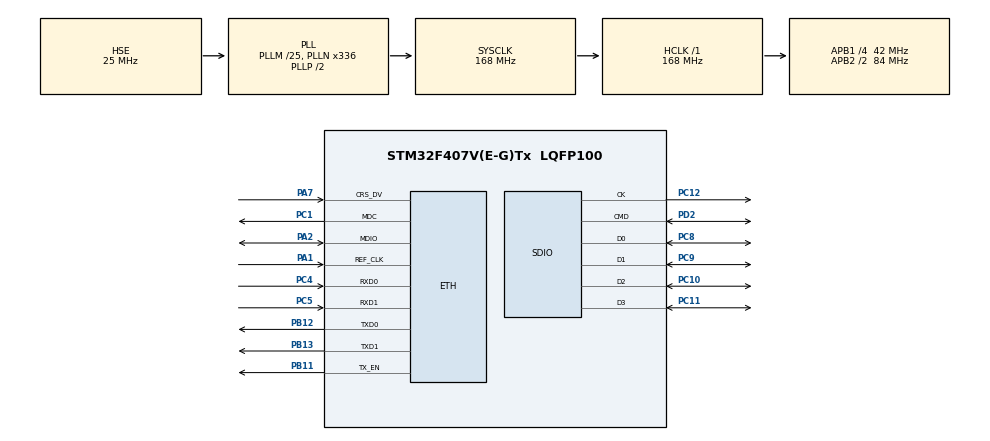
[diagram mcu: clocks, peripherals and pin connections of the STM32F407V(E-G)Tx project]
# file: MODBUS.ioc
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ETH.MediaInterface=HAL_ETH_RMII_MODE
FREERTOS.Tasks01=defaultTask,24,128,StartDefaultTask,Default,NULL,Dynamic,NULL,NULL
FREERTOS.configUSE_NEWLIB_REENTRANT=1
LWIP.BSP.number=1
LWIP.Version=v2.1.2_Cube
LWIP0.BSP.STBoard=false
LWIP0.BSP.api=BSP_COMPONENT_DRIVER
LWIP0.BSP.component=DP83848
LWIP0.BSP.instance=DP83848
LWIP0.BSP.name=Driver_PHY
LWIP0.BSP.semaphore=S_DP83848
LWIP0.BSP.solution=DP83848
Mcu.Family=STM32F4
Mcu.Name=STM32F407V(E-G)Tx
Mcu.Package=LQFP100
NVIC.ETH_IRQn=true\:5\:0\:false\:false\:true\:true\:false\:true\:true
NVIC.PriorityGroup=NVIC_PRIORITYGROUP_4
NVIC.TIM6_DAC_IRQn=true\:15\:0\:false\:false\:true\:false\:false\:true\:true
NVIC.TIM7_IRQn=true\:5\:0\:false\:false\:true\:true\:true\:true\:true
NVIC.TimeBase=TIM6_DAC_IRQn
NVIC.TimeBaseIP=TIM6
PA1.Mode=RMII
PA1.Signal=ETH_REF_CLK
PA13.Mode=Serial_Wire
PA13.Signal=SYS_JTMS-SWDIO
PA14.Mode=Serial_Wire
PA14.Signal=SYS_JTCK-SWCLK
PA2.Mode=RMII
PA2.Signal=ETH_MDIO
PA7.Mode=RMII
PA7.Signal=ETH_CRS_DV
PB11.Mode=RMII
PB11.Signal=ETH_TX_EN
PB12.Mode=RMII
PB12.Signal=ETH_TXD0
PB13.Mode=RMII
PB13.Signal=ETH_TXD1
PC1.Mode=RMII
PC1.Signal=ETH_MDC
PC10.Mode=SD_4_bits_Wide_bus
PC10.Signal=SDIO_D2
PC11.Mode=SD_4_bits_Wide_bus
PC11.Signal=SDIO_D3
PC12.Mode=SD_4_bits_Wide_bus
PC12.Signal=SDIO_CK
PC4.Mode=RMII
PC4.Signal=ETH_RXD0
PC5.Mode=RMII
PC5.Signal=ETH_RXD1
PC8.Mode=SD_4_bits_Wide_bus
PC8.Signal=SDIO_D0
PC9.Mode=SD_4_bits_Wide_bus
PC9.Signal=SDIO_D1
PD2.Mode=SD_4_bits_Wide_bus
PD2.Signal=SDIO_CMD
PH0-OSC_IN.Mode=HSE-External-Oscillator
PH0-OSC_IN.Signal=RCC_OSC_IN
PH1-OSC_OUT.Mode=HSE-External-Oscillator
PH1-OSC_OUT.Signal=RCC_OSC_OUT
ProjectManager.HeapSize=0x200
ProjectManager.StackSize=0x400
ProjectManager.TargetToolchain=STM32CubeIDE
RCC.48MHZClocksFreq_Value=48000000
RCC.AHBFreq_Value=168000000
RCC.APB1CLKDivider=RCC_HCLK_DIV4
RCC.APB1Freq_Value=42000000
RCC.APB1TimFreq_Value=84000000
RCC.APB2CLKDivider=RCC_HCLK_DIV2
RCC.APB2Freq_Value=84000000
RCC.APB2TimFreq_Value=168000000
RCC.CortexFreq_Value=168000000
RCC.EnbaleCSS=true
RCC.HCLKFreq_Value=168000000
RCC.HSE_VALUE=25000000
RCC.HSI_VALUE=16000000
RCC.LSE_VALUE=32768
RCC.PLLM=25
RCC.PLLN=336
RCC.PLLQ=7
RCC.PLLSourceVirtual=RCC_PLLSOURCE_HSE
RCC.SYSCLKFreq_VALUE=168000000
RCC.SYSCLKSource=RCC_SYSCLKSOURCE_PLLCLK
RCC.VCOOutputFreq_Value=336000000
TIM7.Period=249
TIM7.Prescaler=83
VP_FATFS_VS_SDIO.Mode=SDIO
VP_FREERTOS_VS_CMSIS_V2.Mode=CMSIS_V2
VP_LWIP_VS_Enabled.Mode=Enabled
VP_SYS_VS_tim6.Mode=TIM6
VP_TIM7_VS_ClockSourceINT.Mode=Enable_Timer
board=custom

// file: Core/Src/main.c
/* USER CODE BEGIN Header */
/**
  ******************************************************************************
  * @file           : main.c
  * @brief          : Main program body
  ******************************************************************************
  * @attention
  *
  * Copyright (c) 2026 STMicroelectronics.
  * All rights reserved.
  *
  * This software is licensed under terms that can be found in the LICENSE file
  * in the root directory of this software component.
  * If no LICENSE file comes with this software, it is provided AS-IS.
  *
  ******************************************************************************
  */
/* USER CODE END Header */
#include "main.h"
#include "cmsis_os.h"
#include "fatfs.h"
#include "lwip.h"

/* USER CODE BEGIN Includes */
#include "app_system.h"
#include "app_p10.h"
/* USER CODE END Includes */

SD_HandleTypeDef hsd;

TIM_HandleTypeDef htim7;

/* Definitions for defaultTask */
osThreadId_t defaultTaskHandle;
const osThreadAttr_t defaultTask_attributes = {
  .name = "defaultTask",
  .stack_size = 128 * 4,
  .priority = (osPriority_t) osPriorityNormal,
};

void SystemClock_Config(void);
static void MX_GPIO_Init(void);
static void MX_SDIO_SD_Init(void);
static void MX_TIM7_Init(void);
void StartDefaultTask(void *argument);

int main(void)
{

  /* MCU Configuration--------------------------------------------------------*/
  HAL_Init();

  SystemClock_Config();

  /* Initialize all configured peripherals */
  MX_GPIO_Init();
  MX_SDIO_SD_Init();
  MX_FATFS_Init();
  MX_TIM7_Init();

  /* USER CODE BEGIN 2 */
  APP_SystemEarlyInit();

  /* P10 GPIO init + start scan timer (TIM7) */
  APP_P10_Init();
  if (HAL_TIM_Base_Start_IT(&htim7) != HAL_OK)
  {
    Error_Handler();
  }
  /* USER CODE END 2 */

  /* Init scheduler */
  osKernelInitialize();

  /* Create the thread(s) */
  defaultTaskHandle = osThreadNew(StartDefaultTask, NULL, &defaultTask_attributes);

  /* Start scheduler */
  osKernelStart();

  /* Infinite loop */
  while (1)
  {
  }
}

void SystemClock_Config(void)
{
  RCC_OscInitTypeDef RCC_OscInitStruct = {0};
  RCC_ClkInitTypeDef RCC_ClkInitStruct = {0};

  __HAL_RCC_PWR_CLK_ENABLE();
  __HAL_PWR_VOLTAGESCALING_CONFIG(PWR_REGULATOR_VOLTAGE_SCALE1);

  RCC_OscInitStruct.OscillatorType = RCC_OSCILLATORTYPE_HSE;
  RCC_OscInitStruct.HSEState = RCC_HSE_ON;
  RCC_OscInitStruct.PLL.PLLState = RCC_PLL_ON;
  RCC_OscInitStruct.PLL.PLLSource = RCC_PLLSOURCE_HSE;
  RCC_OscInitStruct.PLL.PLLM = 25;
  RCC_OscInitStruct.PLL.PLLN = 336;
  RCC_OscInitStruct.PLL.PLLP = RCC_PLLP_DIV2;
  RCC_OscInitStruct.PLL.PLLQ = 7;
  if (HAL_RCC_OscConfig(&RCC_OscInitStruct) != HAL_OK)
  {
    Error_Handler();
  }

  RCC_ClkInitStruct.ClockType = RCC_CLOCKTYPE_HCLK|RCC_CLOCKTYPE_SYSCLK
                              |RCC_CLOCKTYPE_PCLK1|RCC_CLOCKTYPE_PCLK2;
  RCC_ClkInitStruct.SYSCLKSource = RCC_SYSCLKSOURCE_PLLCLK;
  RCC_ClkInitStruct.AHBCLKDivider = RCC_SYSCLK_DIV1;
  RCC_ClkInitStruct.APB1CLKDivider = RCC_HCLK_DIV4;
  RCC_ClkInitStruct.APB2CLKDivider = RCC_HCLK_DIV2;

  if (HAL_RCC_ClockConfig(&RCC_ClkInitStruct, FLASH_LATENCY_5) != HAL_OK)
  {
    Error_Handler();
  }

  HAL_RCC_EnableCSS();
}

static void MX_SDIO_SD_Init(void)
{
  hsd.Instance = SDIO;
  hsd.Init.ClockEdge = SDIO_CLOCK_EDGE_RISING;
  hsd.Init.ClockBypass = SDIO_CLOCK_BYPASS_DISABLE;
  hsd.Init.ClockPowerSave = SDIO_CLOCK_POWER_SAVE_DISABLE;
  hsd.Init.BusWide = SDIO_BUS_WIDE_4B;
  hsd.Init.HardwareFlowControl = SDIO_HARDWARE_FLOW_CONTROL_DISABLE;
  hsd.Init.ClockDiv = 0;
}

static void MX_TIM7_Init(void)
{
  TIM_MasterConfigTypeDef sMasterConfig = {0};

  htim7.Instance = TIM7;
  htim7.Init.Prescaler = 83;
  htim7.Init.CounterMode = TIM_COUNTERMODE_UP;
  htim7.Init.Period = 249;
  htim7.Init.AutoReloadPreload = TIM_AUTORELOAD_PRELOAD_DISABLE;
  if (HAL_TIM_Base_Init(&htim7) != HAL_OK)
  {
    Error_Handler();
  }
  sMasterConfig.MasterOutputTrigger = TIM_TRGO_RESET;
  sMasterConfig.MasterSlaveMode = TIM_MASTERSLAVEMODE_DISABLE;
  if (HAL_TIMEx_MasterConfigSynchronization(&htim7, &sMasterConfig) != HAL_OK)
  {
    Error_Handler();
  }
}

static void MX_GPIO_Init(void)
{
  __HAL_RCC_GPIOH_CLK_ENABLE();
  __HAL_RCC_GPIOC_CLK_ENABLE();
  __HAL_RCC_GPIOA_CLK_ENABLE();
  __HAL_RCC_GPIOB_CLK_ENABLE();
  __HAL_RCC_GPIOD_CLK_ENABLE();
}

void StartDefaultTask(void *argument)
{
  MX_LWIP_Init();

  /* USER CODE BEGIN 5 */
  APP_SystemStart();

  for(;;)
  {
    osDelay(1);
  }
  /* USER CODE END 5 */
}

void HAL_TIM_PeriodElapsedCallback(TIM_HandleTypeDef *htim)
{
  /* TIM6 = HAL tick */
  if (htim->Instance == TIM6)
  {
    HAL_IncTick();
    return;
  }

  /* TIM7 = P10 scan */
  if (htim->Instance == TIM7)
  {
    APP_P10_ScanISR();
    return;
  }
}

void Error_Handler(void)
{
  __disable_irq();
  while (1)
  {
  }
}
